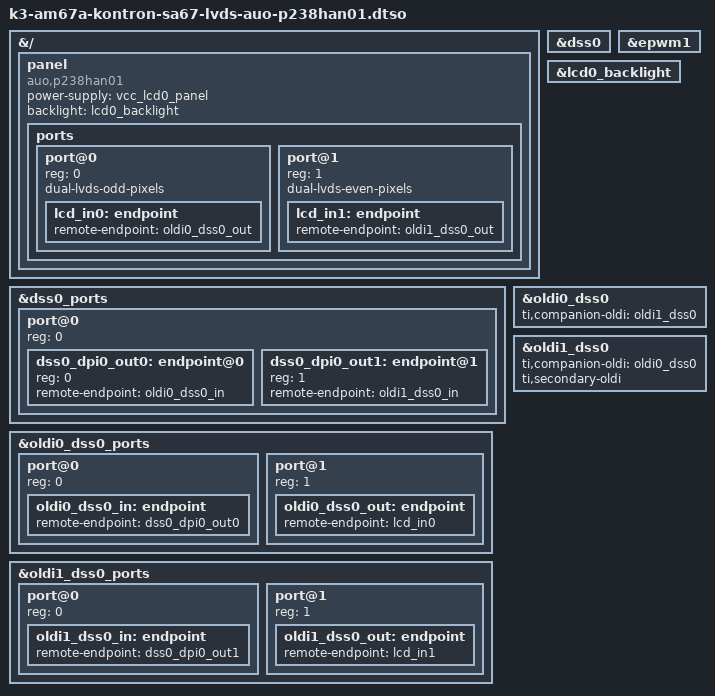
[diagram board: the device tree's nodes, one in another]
/dts-v1/;
/plugin/;

&{/} {
	panel {
		compatible = "auo,p238han01";
		power-supply = <&vcc_lcd0_panel>;
		backlight = <&lcd0_backlight>;
		status = "okay";

		/*
		 * Note that the OLDI TX 0 transmits the odd set of pixels
		 * while the OLDI TX 1 transmits the even set. This is a
		 * fixed configuration in the IP integration and is not
		 * changeable. The properties, "dual-lvds-odd-pixels" and
		 * "dual-lvds-even-pixels" have been used to merely
		 * identify if a Dual Link configuration is required.
		 * Swapping them will cause an error in the dss oldi driver.
		 */
		ports {
			#address-cells = <1>;
			#size-cells = <0>;

			port@0 {
				reg = <0>;
				dual-lvds-odd-pixels;

				lcd_in0: endpoint {
					remote-endpoint = <&oldi0_dss0_out>;
				};
			};
			port@1 {
				reg = <1>;
				dual-lvds-even-pixels;

				lcd_in1: endpoint {
					remote-endpoint = <&oldi1_dss0_out>;
				};
			};
		};
	};
};

&dss0 {
	status = "okay";
};

&dss0_ports {
	#address-cells = <1>;
	#size-cells = <0>;

	port@0 {
		reg = <0>;
		#address-cells = <1>;
		#size-cells = <0>;

		dss0_dpi0_out0: endpoint@0 {
			reg = <0>;
			remote-endpoint = <&oldi0_dss0_in>;
		};

		dss0_dpi0_out1: endpoint@1 {
			reg = <1>;
			remote-endpoint = <&oldi1_dss0_in>;
		};
	};
};

&epwm1 {
	status = "okay";
};

&lcd0_backlight {
	status = "okay";
};

&oldi0_dss0 {
	status = "okay";
	ti,companion-oldi = <&oldi1_dss0>;
};

&oldi1_dss0 {
	status = "okay";
	ti,companion-oldi = <&oldi0_dss0>;
	ti,secondary-oldi;
};

&oldi0_dss0_ports {
	#address-cells = <1>;
	#size-cells = <0>;

	port@0 {
		reg = <0>;

		oldi0_dss0_in: endpoint {
			remote-endpoint = <&dss0_dpi0_out0>;
		};
	};

	port@1 {
		reg = <1>;

		oldi0_dss0_out: endpoint {
			remote-endpoint = <&lcd_in0>;
		};
	};
};

&oldi1_dss0_ports {
	#address-cells = <1>;
	#size-cells = <0>;

	port@0 {
		reg = <0>;

		oldi1_dss0_in: endpoint {
			remote-endpoint = <&dss0_dpi0_out1>;
		};
	};

	port@1 {
		reg = <1>;

		oldi1_dss0_out: endpoint {
			remote-endpoint = <&lcd_in1>;
		};
	};
};
